# CYBL11573_56LQXI register map
File version: 0.1
PRoC BLE
Registers are 32-bit, read-write, no defined reset value unless marked. A register's access mark holds for its fields unless they carry their own. Offsets are from the block's base; lines under a group give offsets from that group; [hi:lo] are bit positions; {n}, {i} and the like mark numbered series; 'fields as' and 'values as' point back to an identical list; <NAME> marks a mode.

## Memory map
0x00000000 I2S_1
0x00000000 PWM_Servo
0x00000000 TCPWM_1
0x00000000 ADC_SAR_Seq_1 — Sequencing SAR ADC
0x40000000 DMAC — DMAC Registers

## I2S_1
Base 0x00000000
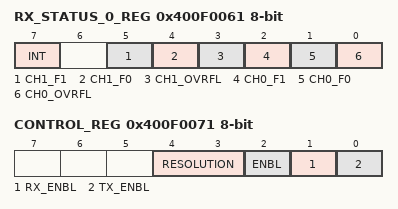
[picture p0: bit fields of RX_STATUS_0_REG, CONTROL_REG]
0x400F0061 RX_STATUS_0_REG 8-bit
  [7] INT ro — Interrupt bit
  [5] CH1_F1 ro — Stereo channel 1 FIFO 1 state
    0=EMPTY; 1=NOT_EMPTY
  [4] CH1_F0 ro — Stereo channel 1 FIFO 0 state
    0=EMPTY; 1=NOT_EMPTY
  [3] CH1_OVRFL ro — Stereo channel 1 FIFO overflow
    0=NO_OVERFLOW; 1=OVERFLOW
  [2] CH0_F1 ro — Stereo channel 0 FIFO 1 state
    0=EMPTY; 1=NOT_EMPTY
  [1] CH0_F0 ro — Stereo channel 0 FIFO 0 state
    0=EMPTY; 1=NOT_EMPTY
  [0] CH0_OVRFL ro — Stereo channel 0 FIFO overflow
    0=NO_OVERFLOW; 1=OVERFLOW
0x400F0071 CONTROL_REG 8-bit
  [4:3] RESOLUTION — Specifies data bits value. Applicable only if dynamic bit resolution is selected.
    0=Cy8_BIT; 1=Cy16_BIT; 2=Cy24_BIT; 3=Cy32_BIT
  [2] ENBL — Starts the generation of the WS and SCK outputs.
    1=ENABLED; 0=DISABLED
  [1] RX_ENBL — Enables Rx direction. Applicable only if Rx direction presents for the component.
    1=ENABLED; 0=DISABLED
  [0] TX_ENBL — Enables Tx direction. Applicable only if Tx direction presents for the component.
    1=ENABLED; 0=DISABLED

## PWM_Servo
Base 0x00000000
0x40200108 COUNTER — Current counter value
0x4020010C CC — Compare / capture value
0x40200110 CC_BUF — Compare / capture buffer value
0x40200114 PERIOD — Period value
0x40200118 PERIOD_BUF — Period buffer value

## TCPWM_1
Base 0x00000000
0x40200148 COUNTER — Current counter value
0x4020014C CC — Compare / capture value
0x40200150 CC_BUF — Compare / capture buffer value
0x40200154 PERIOD — Period value
0x40200158 PERIOD_BUF — Period buffer value
